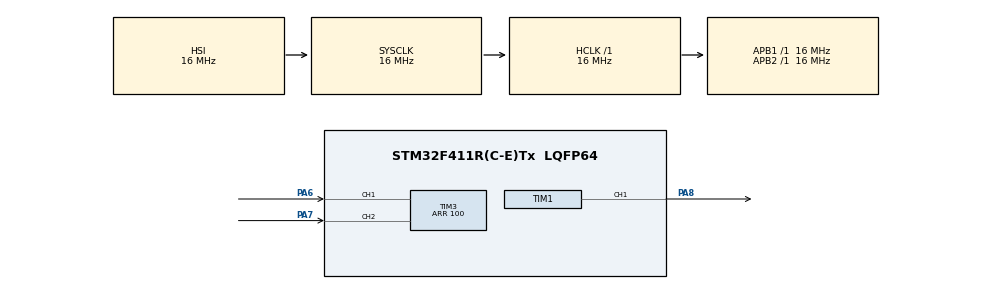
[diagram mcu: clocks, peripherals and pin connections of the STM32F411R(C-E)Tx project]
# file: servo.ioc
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Mcu.Family=STM32F4
Mcu.Name=STM32F411R(C-E)Tx
Mcu.Package=LQFP64
NVIC.PriorityGroup=NVIC_PRIORITYGROUP_4
PA6.Signal=S_TIM3_CH1
PA7.Signal=S_TIM3_CH2
PA8.Signal=S_TIM1_CH1
ProjectManager.HeapSize=0x200
ProjectManager.StackSize=0x400
ProjectManager.TargetToolchain=STM32CubeIDE
RCC.AHBFreq_Value=16000000
RCC.APB1Freq_Value=16000000
RCC.APB2Freq_Value=16000000
RCC.CortexFreq_Value=16000000
RCC.HSE_VALUE=25000000
RCC.HSI_VALUE=16000000
RCC.LSE_VALUE=32768
RCC.SYSCLKFreq_VALUE=16000000
RCC.VCOOutputFreq_Value=192000000
SH.S_TIM1_CH1.0=TIM1_CH1,PWM Generation1 CH1
SH.S_TIM3_CH1.0=TIM3_CH1,Encoder_Interface
SH.S_TIM3_CH2.0=TIM3_CH2,Encoder_Interface
TIM1.Channel-PWM\ Generation1\ CH1=TIM_CHANNEL_1
TIM1.Period=20000-1
TIM1.Prescaler=15
TIM1.Pulse-PWM\ Generation1\ CH1=1500-1
TIM3.EncoderMode=TIM_ENCODERMODE_TI12
TIM3.Period=100
VP_TIM1_VS_ClockSourceINT.Mode=Internal
board=custom

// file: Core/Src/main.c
/* USER CODE BEGIN Header */
/**
  ******************************************************************************
  * @file           : main.c
  * @brief          : Main program body
  ******************************************************************************
  * @attention
  *
  * Copyright (c) 2023 STMicroelectronics.
  * All rights reserved.
  *
  * This software is licensed under terms that can be found in the LICENSE file
  * in the root directory of this software component.
  * If no LICENSE file comes with this software, it is provided AS-IS.
  *
  ******************************************************************************
  */
/* USER CODE END Header */
#include "main.h"

TIM_HandleTypeDef htim1;
TIM_HandleTypeDef htim3;

void SystemClock_Config(void);
static void MX_GPIO_Init(void);
static void MX_TIM1_Init(void);
static void MX_TIM3_Init(void);

/* USER CODE BEGIN 0 */
#define OneRotatioPulses 20
uint8_t cnt1, cnt2, diff, speed, dir;
uint32_t tick;

long map(long x, long in_min, long in_max, long out_min, long out_max) {
  return (x - in_min) * (out_max - out_min) / (in_max - in_min) + out_min;
}

void setServo(int inData){
	htim1.Instance->CCR1 = map(inData, 0, 100, 700, 2500); //1000~2000 �?� 줘야하는�?� 들어오는 값�?� 0~100
	//180�?� 움�?�?�게 하고 싶으면 999>700, 1999>2500
}
/* USER CODE END 0 */

int main(void)
{

  /* MCU Configuration--------------------------------------------------------*/

  /* Reset of all peripherals, Initializes the Flash interface and the Systick. */
  HAL_Init();

  /* Configure the system clock */
  SystemClock_Config();

  /* Initialize all configured peripherals */
  MX_GPIO_Init();
  MX_TIM1_Init();
  MX_TIM3_Init();
  /* USER CODE BEGIN 2 */
HAL_TIM_PWM_Start(&htim1, TIM_CHANNEL_1);

HAL_TIM_Encoder_Start(&htim3, TIM_CHANNEL_ALL);

/*HAL_TIM_Encoder_Start(&htim3,TIM_CHANNEL_ALL);
HAL_TIM_OC_Start(&htim4, TIM_CHANNEL_1);
HAL_TIM_OC_Start(&htim4, TIM_CHANNEL_2);

cnt1 = TIM3->CNT;
tick = HAL_GetTick();*/
//시스틱 사용할 때 hamdler�?서 hal_intick 으로 �?�해서 전�?�?� 켜지면 무한으로 1ms마다 1씩 �?가함
  /* USER CODE END 2 */

  /* Infinite loop */
  while (1)
  {

    /* USER CODE BEGIN 3 */
	  setServo(htim3.Instance->CNT);
	  HAL_Delay(50);
	  /*for(int i = 0; i <= 100; i++){
		  setServo(i);
		  HAL_Delay(10);
	  }
	  for(int i = 0; i >= 100; i++){
		  setServo(i);
		  HAL_Delay(10);
	  }
	  //왼쪽 오른쪽 왔다 갓다 하게�?� 만들기*/
	  /* if(HAL_GetTick() - tick > 1000L) {
		  //오랜시간�?� 걸리면 L�?� 붙여주면 �?�
		  //1초�? 한번씩 �?� 안으로 들어오겠다는 �?임
		  cnt2 = TIM3->CNT; //1초�?�안 얼만�?� �?가 혹�?� �?소했는지 값�?� 확�?�할 수 있�?�

		  //chec direction
		  if(__HAL_TIM_IS_TIM_COUNTING_DOWN(&htim3)){9
			  dir - 1;
			  if((cnt2 > cnt1) && (cnt2 - cnt1 < 100))dir = 0;
		  }
		  else {
			  dir = 0; //up
			  if((cnt1 > cnt2) && (cnt1 - cnt2 < 100)) dir = 1;
		  }

		  if (dir){
			  if(cnt1 >= cnt2) diff = cnt1 - cnt2;
			  else diff = (TIM3->ARR + cnt1) - cnt2;
			  //ARR = 65535;
		  }
		  else {
			  if(cnt2 >= cnt1) diff = cnt2 - cnt1;
			  else diff = (TIM3->ARR + cnt2) - cnt1;
		  }// 방향�?� 어�?방향�?�지

		  //회전 �?�?�가 얼마나 빠른지 체�?�
		  if((TIM3->SMCR & 0x03) == 0x03){
			  speed = diff * 60 / 4 / OneRotatioPulses;
		  }
		  else {
			  speed = diff * 60 / 2 / OneRotatioPulses;
		  }

		  tick = HAL_GetTick(); //tick�?� 다�?��?� 위해서
		  cnt1 = TIM3->CNT;

		  setServo(map(cnt1, 0, 65535, 0, 100));
	  }//main함수가 닫힘

  }//main if가 닫힘 */
  }
  /* USER CODE END 3 */
}

void SystemClock_Config(void)
{
  RCC_OscInitTypeDef RCC_OscInitStruct = {0};
  RCC_ClkInitTypeDef RCC_ClkInitStruct = {0};

  /** Configure the main internal regulator output voltage
  */
  __HAL_RCC_PWR_CLK_ENABLE();
  __HAL_PWR_VOLTAGESCALING_CONFIG(PWR_REGULATOR_VOLTAGE_SCALE1);

  /** Initializes the RCC Oscillators according to the specified parameters
  * in the RCC_OscInitTypeDef structure.
  */
  RCC_OscInitStruct.OscillatorType = RCC_OSCILLATORTYPE_HSI;
  RCC_OscInitStruct.HSIState = RCC_HSI_ON;
  RCC_OscInitStruct.HSICalibrationValue = RCC_HSICALIBRATION_DEFAULT;
  RCC_OscInitStruct.PLL.PLLState = RCC_PLL_NONE;
  if (HAL_RCC_OscConfig(&RCC_OscInitStruct) != HAL_OK)
  {
    Error_Handler();
  }

  /** Initializes the CPU, AHB and APB buses clocks
  */
  RCC_ClkInitStruct.ClockType = RCC_CLOCKTYPE_HCLK|RCC_CLOCKTYPE_SYSCLK
                              |RCC_CLOCKTYPE_PCLK1|RCC_CLOCKTYPE_PCLK2;
  RCC_ClkInitStruct.SYSCLKSource = RCC_SYSCLKSOURCE_HSI;
  RCC_ClkInitStruct.AHBCLKDivider = RCC_SYSCLK_DIV1;
  RCC_ClkInitStruct.APB1CLKDivider = RCC_HCLK_DIV1;
  RCC_ClkInitStruct.APB2CLKDivider = RCC_HCLK_DIV1;

  if (HAL_RCC_ClockConfig(&RCC_ClkInitStruct, FLASH_LATENCY_0) != HAL_OK)
  {
    Error_Handler();
  }
}

static void MX_TIM1_Init(void)
{

  TIM_ClockConfigTypeDef sClockSourceConfig = {0};
  TIM_MasterConfigTypeDef sMasterConfig = {0};
  TIM_OC_InitTypeDef sConfigOC = {0};
  TIM_BreakDeadTimeConfigTypeDef sBreakDeadTimeConfig = {0};

  htim1.Instance = TIM1;
  htim1.Init.Prescaler = 15;
  htim1.Init.CounterMode = TIM_COUNTERMODE_UP;
  htim1.Init.Period = 20000-1;
  htim1.Init.ClockDivision = TIM_CLOCKDIVISION_DIV1;
  htim1.Init.RepetitionCounter = 0;
  htim1.Init.AutoReloadPreload = TIM_AUTORELOAD_PRELOAD_DISABLE;
  if (HAL_TIM_Base_Init(&htim1) != HAL_OK)
  {
    Error_Handler();
  }
  sClockSourceConfig.ClockSource = TIM_CLOCKSOURCE_INTERNAL;
  if (HAL_TIM_ConfigClockSource(&htim1, &sClockSourceConfig) != HAL_OK)
  {
    Error_Handler();
  }
  if (HAL_TIM_PWM_Init(&htim1) != HAL_OK)
  {
    Error_Handler();
  }
  sMasterConfig.MasterOutputTrigger = TIM_TRGO_RESET;
  sMasterConfig.MasterSlaveMode = TIM_MASTERSLAVEMODE_DISABLE;
  if (HAL_TIMEx_MasterConfigSynchronization(&htim1, &sMasterConfig) != HAL_OK)
  {
    Error_Handler();
  }
  sConfigOC.OCMode = TIM_OCMODE_PWM1;
  sConfigOC.Pulse = 1500-1;
  sConfigOC.OCPolarity = TIM_OCPOLARITY_HIGH;
  sConfigOC.OCNPolarity = TIM_OCNPOLARITY_HIGH;
  sConfigOC.OCFastMode = TIM_OCFAST_DISABLE;
  sConfigOC.OCIdleState = TIM_OCIDLESTATE_RESET;
  sConfigOC.OCNIdleState = TIM_OCNIDLESTATE_RESET;
  if (HAL_TIM_PWM_ConfigChannel(&htim1, &sConfigOC, TIM_CHANNEL_1) != HAL_OK)
  {
    Error_Handler();
  }
  sBreakDeadTimeConfig.OffStateRunMode = TIM_OSSR_DISABLE;
  sBreakDeadTimeConfig.OffStateIDLEMode = TIM_OSSI_DISABLE;
  sBreakDeadTimeConfig.LockLevel = TIM_LOCKLEVEL_OFF;
  sBreakDeadTimeConfig.DeadTime = 0;
  sBreakDeadTimeConfig.BreakState = TIM_BREAK_DISABLE;
  sBreakDeadTimeConfig.BreakPolarity = TIM_BREAKPOLARITY_HIGH;
  sBreakDeadTimeConfig.AutomaticOutput = TIM_AUTOMATICOUTPUT_DISABLE;
  if (HAL_TIMEx_ConfigBreakDeadTime(&htim1, &sBreakDeadTimeConfig) != HAL_OK)
  {
    Error_Handler();
  }
  HAL_TIM_MspPostInit(&htim1);

}

static void MX_TIM3_Init(void)
{

  TIM_Encoder_InitTypeDef sConfig = {0};
  TIM_MasterConfigTypeDef sMasterConfig = {0};

  htim3.Instance = TIM3;
  htim3.Init.Prescaler = 0;
  htim3.Init.CounterMode = TIM_COUNTERMODE_UP;
  htim3.Init.Period = 100;
  htim3.Init.ClockDivision = TIM_CLOCKDIVISION_DIV1;
  htim3.Init.AutoReloadPreload = TIM_AUTORELOAD_PRELOAD_DISABLE;
  sConfig.EncoderMode = TIM_ENCODERMODE_TI12;
  sConfig.IC1Polarity = TIM_ICPOLARITY_RISING;
  sConfig.IC1Selection = TIM_ICSELECTION_DIRECTTI;
  sConfig.IC1Prescaler = TIM_ICPSC_DIV1;
  sConfig.IC1Filter = 0;
  sConfig.IC2Polarity = TIM_ICPOLARITY_RISING;
  sConfig.IC2Selection = TIM_ICSELECTION_DIRECTTI;
  sConfig.IC2Prescaler = TIM_ICPSC_DIV1;
  sConfig.IC2Filter = 0;
  if (HAL_TIM_Encoder_Init(&htim3, &sConfig) != HAL_OK)
  {
    Error_Handler();
  }
  sMasterConfig.MasterOutputTrigger = TIM_TRGO_RESET;
  sMasterConfig.MasterSlaveMode = TIM_MASTERSLAVEMODE_DISABLE;
  if (HAL_TIMEx_MasterConfigSynchronization(&htim3, &sMasterConfig) != HAL_OK)
  {
    Error_Handler();
  }

}

static void MX_GPIO_Init(void)
{

  /* GPIO Ports Clock Enable */
  __HAL_RCC_GPIOA_CLK_ENABLE();

}

void Error_Handler(void)
{
  __disable_irq();
  while (1)
  {
  }
}
